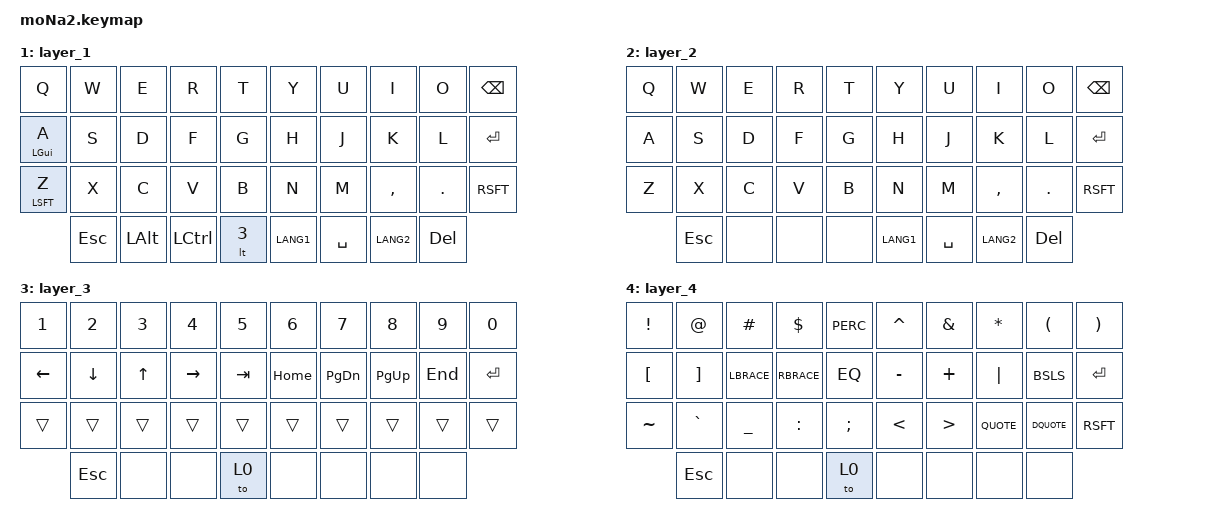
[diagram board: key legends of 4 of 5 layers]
// moNa2.keymap - Refactored for Windows, Mac, iPad profiles with IME switch on thumbs
#include <behaviors.dtsi>
#include <dt-bindings/zmk/bt.h>
#include <dt-bindings/zmk/keys.h>
#include <dt-bindings/zmk/pointing.h>

&mt {
    flavor = "balanced";
    quick-tap-ms = <200>;
};

/ {
    keymap {
        compatible = "zmk,keymap";

        // Windows Layer (default)
        default_layer {
            bindings = <
  &kp Q       &kp W       &kp E       &kp R       &kp T              &kp Y       &kp U       &kp I       &kp O       &kp BACKSPACE
  &mt LCTRL A &kp S       &kp D       &kp F       &kp G              &kp H       &kp J       &kp K       &kp L       &kp ENTER
  &mt LSFT Z  &kp X       &kp C       &kp V       &kp B              &kp N       &kp M       &kp COMMA   &kp DOT     &mkp LCLK &mkp RCLK &kp RSFT
           &kp ESC       &kp LGUI    &kp LALT    &lt 3               &kp LANG1    &kp SPACE    &kp LANG2    &kp DEL
            >;
        };

        // Mac Layer
        layer_1 {
            bindings = <
  &kp Q       &kp W       &kp E       &kp R       &kp T              &kp Y       &kp U       &kp I       &kp O       &kp BSPC
  &mt LGUI A  &kp S       &kp D       &kp F       &kp G              &kp H       &kp J       &kp K       &kp L       &kp RET
  &mt LSFT Z  &kp X       &kp C       &kp V       &kp B              &kp N       &kp M       &kp COMMA   &kp DOT     &kp RSFT
           &kp ESC       &kp LALT    &kp LCTRL   &lt 3               &kp LANG1    &kp SPACE    &kp LANG2    &kp DEL
            >;
        };

        // iPad Layer
        layer_2 {
            bindings = <
  &kp Q       &kp W       &kp E       &kp R       &kp T              &kp Y       &kp U       &kp I       &kp O       &kp BSPC
  &kp A       &kp S       &kp D       &kp F       &kp G              &kp H       &kp J       &kp K       &kp L       &kp RET
  &kp Z       &kp X       &kp C       &kp V       &kp B              &kp N       &kp M       &kp COMMA   &kp DOT     &kp RSFT
           &kp ESC       &none       &none       &none              &kp LANG1    &kp SPACE    &kp LANG2    &kp DEL
            >;
        };

        // Nav+Num Layer
        layer_3 {
            bindings = <
  &kp 1       &kp 2       &kp 3       &kp 4       &kp 5              &kp 6       &kp 7       &kp 8       &kp 9       &kp 0
  &kp LEFT    &kp DOWN    &kp UP      &kp RIGHT   &kp TAB            &kp HOME    &kp PG_DN   &kp PG_UP   &kp END     &kp RET
  &trans      &trans      &trans      &trans      &trans             &trans      &trans      &trans      &trans      &trans
           &kp ESC       &none       &none       &to 0              &none       &none       &none       &none
            >;
        };

        // Symbol / Code Layer
        layer_4 {
            bindings = <
  &kp EXCL    &kp AT      &kp HASH    &kp DLLR    &kp PERC           &kp CARET   &kp AMPS    &kp ASTERISK &kp LPAR    &kp RPAR
  &kp LBKT    &kp RBKT    &kp LBRACE  &kp RBRACE  &kp EQ             &kp MINUS   &kp PLUS    &kp PIPE     &kp BSLS    &kp RET
  &kp TILDE   &kp GRAVE   &kp UNDER   &kp COLON   &kp SEMI           &kp LT      &kp GT      &kp QUOTE    &kp DQUOTE  &kp RSFT
           &kp ESC       &none       &none       &to 0              &none       &none       &none       &none
            >;
        };
    };
};
